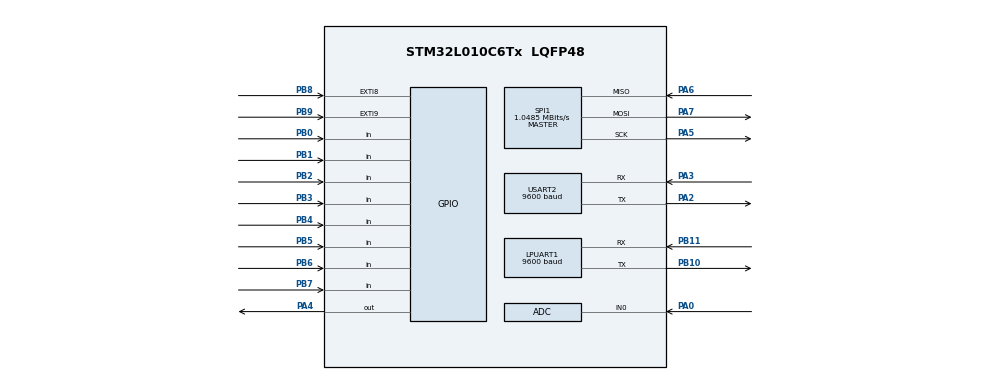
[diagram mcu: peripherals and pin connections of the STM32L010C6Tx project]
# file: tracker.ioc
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ADC.SamplingTime=ADC_SAMPLETIME_39CYCLES_5
Dma.ADC.0.Direction=DMA_PERIPH_TO_MEMORY
Dma.ADC.0.Instance=DMA1_Channel1
Dma.ADC.0.MemDataAlignment=DMA_MDATAALIGN_HALFWORD
Dma.ADC.0.MemInc=DMA_MINC_ENABLE
Dma.ADC.0.Mode=DMA_NORMAL
Dma.ADC.0.PeriphDataAlignment=DMA_PDATAALIGN_HALFWORD
Dma.ADC.0.PeriphInc=DMA_PINC_DISABLE
Dma.ADC.0.Priority=DMA_PRIORITY_LOW
Dma.Request0=ADC
FREERTOS.INCLUDE_uxTaskPriorityGet=0
FREERTOS.INCLUDE_vTaskDelayUntil=0
FREERTOS.INCLUDE_vTaskDelete=0
FREERTOS.INCLUDE_vTaskPrioritySet=0
FREERTOS.INCLUDE_vTaskSuspend=0
FREERTOS.MEMORY_ALLOCATION=1
FREERTOS.Tasks01=defaultTask,0,128,StartDefaultTask,Default,NULL,Static,defaultTaskBuffer,defaultTaskControlBlock
FREERTOS.configENABLE_BACKWARD_COMPATIBILITY=0
FREERTOS.configENABLE_FPU=0
FREERTOS.configUSE_MUTEXES=0
FREERTOS.configUSE_NEWLIB_REENTRANT=0
FREERTOS.configUSE_TASK_NOTIFICATIONS=1
LPUART1.BaudRate=9600
LPUART1.DMADisableonRxErrorParam=UART_ADVFEATURE_DMA_DISABLEONRXERROR
LPUART1.OverrunDisableParam=UART_ADVFEATURE_OVERRUN_DISABLE
LPUART1.RxPinLevelInvertParam=UART_ADVFEATURE_RXINV_DISABLE
LPUART1.WordLength=UART_WORDLENGTH_8B
Mcu.Family=STM32L0
Mcu.Name=STM32L010C6Tx
Mcu.Package=LQFP48
NVIC.ADC1_IRQn=true\:3\:0\:false\:false\:true\:true\:true\:true\:true
NVIC.DMA1_Channel1_IRQn=true\:3\:0\:false\:false\:true\:true\:false\:true\:true
NVIC.EXTI4_15_IRQn=true\:3\:0\:false\:false\:true\:true\:true\:true\:true
NVIC.LPUART1_IRQn=true\:3\:0\:false\:false\:true\:true\:true\:true\:true
NVIC.SPI1_IRQn=true\:3\:0\:false\:false\:true\:true\:true\:true\:true
NVIC.TIM2_IRQn=true\:3\:0\:false\:false\:true\:false\:false\:true\:true
NVIC.TimeBase=TIM2_IRQn
NVIC.TimeBaseIP=TIM2
NVIC.USART2_IRQn=true\:3\:0\:false\:false\:true\:true\:true\:true\:true
PA0.Mode=IN0
PA0.Signal=ADC_IN0
PA10.Signal=I2C1_SDA
PA13.Mode=Serial_Wire
PA13.Signal=SYS_SWDIO
PA14.Mode=Serial_Wire
PA14.Signal=SYS_SWCLK
PA2.Mode=Asynchronous
PA2.Signal=USART2_TX
PA3.Mode=Asynchronous
PA3.Signal=USART2_RX
PA4.Signal=GPIO_Output
PA5.Mode=Full_Duplex_Master
PA5.Signal=SPI1_SCK
PA6.Mode=Full_Duplex_Master
PA6.Signal=SPI1_MISO
PA7.Mode=Full_Duplex_Master
PA7.Signal=SPI1_MOSI
PA9.Signal=I2C1_SCL
PB0.Signal=GPIO_Input
PB1.Signal=GPIO_Input
PB10.Mode=Asynchronous
PB10.Signal=LPUART1_TX
PB11.Mode=Asynchronous
PB11.Signal=LPUART1_RX
PB2.Signal=GPIO_Input
PB3.Signal=GPIO_Input
PB4.Signal=GPIO_Input
PB5.Signal=GPIO_Input
PB6.Signal=GPIO_Input
PB7.Signal=GPIO_Input
PB8.Signal=GPXTI8
PB9.Signal=GPXTI9
ProjectManager.HeapSize=0x200
ProjectManager.StackSize=0x400
ProjectManager.TargetToolchain=STM32CubeIDE
RCC.AHBFreq_Value=2097000
RCC.APB1Freq_Value=2097000
RCC.APB1TimFreq_Value=2097000
RCC.APB2Freq_Value=2097000
RCC.APB2TimFreq_Value=2097000
RCC.HSE_VALUE=8000000
RCC.HSI16_VALUE=16000000
RCC.HSI_VALUE=16000000
RCC.LSE_VALUE=32768
RCC.MSI_VALUE=2097000
RCC.SYSCLKFreq_VALUE=2097000
RCC.VCOOutputFreq_Value=48000000
SPI1.CalculateBaudRate=1.0485 MBits/s
SPI1.Direction=SPI_DIRECTION_2LINES
SPI1.Mode=SPI_MODE_MASTER
SPI1.VirtualType=VM_MASTER
USART2.BaudRate=9600
USART2.DMADisableonRxErrorParam=ADVFEATURE_DMA_DISABLEONRXERROR
USART2.OverrunDisableParam=ADVFEATURE_OVERRUN_DISABLE
USART2.VirtualMode=VM_ASYNC
VP_FREERTOS_VS_CMSIS_V1.Mode=CMSIS_V1
VP_SYS_VS_tim2.Mode=TIM2
board=custom

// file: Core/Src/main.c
/* USER CODE BEGIN Header */
/**
  ******************************************************************************
  * @file           : main.c
  * @brief          : Main program body
  ******************************************************************************
  * @attention
  *
  * Copyright (c) 2023 STMicroelectronics.
  * All rights reserved.
  *
  * This software is licensed under terms that can be found in the LICENSE file
  * in the root directory of this software component.
  * If no LICENSE file comes with this software, it is provided AS-IS.
  *
  ******************************************************************************
  */
/* USER CODE END Header */
#include "main.h"
#include "cmsis_os.h"
#include "adc.h"
#include "dma.h"
#include "usart.h"
#include "spi.h"
#include "gpio.h"

/* USER CODE BEGIN Includes */

#include <init.h>

/* USER CODE END Includes */

void SystemClock_Config(void);
void MX_FREERTOS_Init(void);

int main(void)
{

  /* MCU Configuration--------------------------------------------------------*/

  /* Reset of all peripherals, Initializes the Flash interface and the Systick. */
  HAL_Init();

  /* Configure the system clock */
  SystemClock_Config();

  /* Initialize all configured peripherals */
  MX_GPIO_Init();
  MX_SPI1_Init();
  MX_DMA_Init();
  MX_ADC_Init();
  MX_USART2_UART_Init();
  MX_LPUART1_UART_Init();
  /* USER CODE BEGIN 2 */

  init();

  /* USER CODE END 2 */

  /* Call init function for freertos objects (in freertos.c) */
  MX_FREERTOS_Init();

  /* Start scheduler */
  osKernelStart();

  /* We should never get here as control is now taken by the scheduler */
  /* Infinite loop */
  while (1)
  {

  }
}

void SystemClock_Config(void)
{
  LL_FLASH_SetLatency(LL_FLASH_LATENCY_0);
  while(LL_FLASH_GetLatency()!= LL_FLASH_LATENCY_0)
  {
  }
  LL_PWR_SetRegulVoltageScaling(LL_PWR_REGU_VOLTAGE_SCALE1);
  LL_RCC_MSI_Enable();

   /* Wait till MSI is ready */
  while(LL_RCC_MSI_IsReady() != 1)
  {

  }
  LL_RCC_MSI_SetRange(LL_RCC_MSIRANGE_5);
  LL_RCC_MSI_SetCalibTrimming(0);
  LL_RCC_SetAHBPrescaler(LL_RCC_SYSCLK_DIV_1);
  LL_RCC_SetAPB1Prescaler(LL_RCC_APB1_DIV_1);
  LL_RCC_SetAPB2Prescaler(LL_RCC_APB2_DIV_1);
  LL_RCC_SetSysClkSource(LL_RCC_SYS_CLKSOURCE_MSI);

   /* Wait till System clock is ready */
  while(LL_RCC_GetSysClkSource() != LL_RCC_SYS_CLKSOURCE_STATUS_MSI)
  {

  }
  LL_SetSystemCoreClock(2097000);

   /* Update the time base */
  if (HAL_InitTick (TICK_INT_PRIORITY) != HAL_OK)
  {
    Error_Handler();
  }
  LL_RCC_SetUSARTClockSource(LL_RCC_USART2_CLKSOURCE_PCLK1);
  LL_RCC_SetLPUARTClockSource(LL_RCC_LPUART1_CLKSOURCE_PCLK1);
}

void HAL_TIM_PeriodElapsedCallback(TIM_HandleTypeDef *htim)
{
  if (htim->Instance == TIM2) {
    HAL_IncTick();
  }
}

void Error_Handler(void)
{
  __disable_irq();
  while (1)
  {
  }
}
